# SN32F290 register map
Vendor: SONIX; File version: 2026.10.03
CPU: CM0 r0p0, little endian, no MPU, no FPU, 2 interrupt priority bits
Registers are 32-bit, read-write, reset 0x0 unless marked. A register's access mark holds for its fields unless they carry their own. Offsets are from the block's base; [hi:lo] are bit positions.

## SN_SYS0 — System Control Registers 0
Base 0x40060000
0x00 ANBCTRL reset 0x1 (reset mask 0x35) — Offset:0x00 Analog Block Control Register
  [10:5] EHSFREQ — EHS XTAL frequency range
    0=Low_4 (Less equal than 12MHz); 1=High_23 (Greater than 12MHz)
  [8:4] EHSEN — EHS XTAL enable
    0=Disable_434 (Disable EHS Xtal); 1=Enable_145 (Enable EHS Xtal)
  [4:2] ELSEN — ELS XTAL enable
    0=Disable_434 (Disable ELS Xtal); 1=Enable_145 (Enable ELS Xtal)
  [0] IHRCEN — IHRC enable
    0=Disable_434 (Disable IHRC); 1=Enable_145 (Enable IHRC)
0x04 PLLCTRL (reset mask 0x9027) — Offset:0x04 PLL Control Register
  [30:15] PLLEN — PLL enable
    0=Disable_434 (Disable PLL); 1=Enable_145 (Enable PLL)
  [24:12] PLLCLKSEL — PLL clock source
    0=IHRC_3 (12MHz); 1=EHS_XTAL_5 (10MHz~25MHz)
  [10:5] PSEL — P value
    0=V_2 (P=2); 1=V_4_16 (P=4)
  [2:0] MSEL — M value
    0=V_000b_5 (M=4); 1=V_001b_13 (M=6); 2=V_010b_18 (M=8); 3=V_011b_3 (M=10); 4=V_100b (M=12)
0x08 CSST ro reset 0x1 (reset mask 0x55) — Offset:0x08 Clock Source Status Register
  [12:6] PLLRDY — PLL ready flag
    0=Not_Locked (PLL is Not locked); 1=Locked (PLL is locked)
  [8:4] EHSRDY — EHS XTAL ready flag
    0=Not_Ready_4 (EHS Xtal is Not Ready); 1=Ready_8 (EHS Xtal is Ready)
  [4:2] ELSRDY — ELS XTAL ready flag
    0=Not_Ready_4 (ELS Xtal is Not Ready); 1=Ready_8 (ELS Xtal is Ready)
  [0] IHRCRDY — IHRC ready flag
    0=Not_Ready_4 (IHRC is Not Ready); 1=Ready_8 (IHRC is Ready)
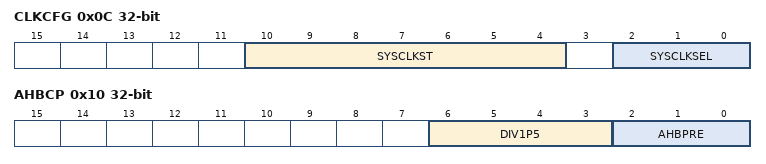
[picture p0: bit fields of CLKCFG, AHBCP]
0x0C CLKCFG (reset mask 0x77) — Offset:0x0C System Clock Configuration Register
  [10:4] SYSCLKST ro — System clock switch status
    0=IHRC_3 (IHRC is used as system clock); 1=ILRC_2 (ILRC is used as system clock); 2=EHS_XTAL_5 (EHS XTAL is used as system clock); 3=ELS_XTAL_2 (ELS XTAL is used as system clock); 4=PLL (PLL output is used as system clock)
  [2:0] SYSCLKSEL — System clock source selection
    0=IHRC_3 (HCLK=IHRC); 1=ILRC_2 (HCLK=ILRC); 2=EHS_XTAL_5 (HCLK=EHS XTAL); 3=ELS_XTAL_2 (HCLK=ELS XTAL); 4=PLL_Output (HCLK=PLL output)
0x10 AHBCP (reset mask 0xF) — Offset:0x10 AHB Clock Prescale Register
  [6:3] DIV1P5 — SYSCLK prescaler
    0=DIV1 (SYSCLK = SYSCLK/1); 1=SYSCLK = SYSCLK/1.5
  [2:0] AHBPRE — AHB clock source prescaler
    0=V_000b_5 (FAHB=FSYSCLK/1); 1=V_001b_13 (FAHB=FSYSCLK/2); 2=V_010b_18 (FAHB=FSYSCLK/4); 3=V_011b_3 (FAHB=FSYSCLK/8); 4=V_100b (FAHB=FSYSCLK/16); 5=V_101b_5 (FAHB=FSYSCLK/32); 6=V_110b (FAHB=FSYSCLK/64); 7=V_111b_11 (FAHB=FSYSCLK/128)
0x14 RSTST reset 0x11 (reset mask 0x1F) — Offset:0x14 System Reset Status Register
  [8:4] PORRSTF — POR reset flag
    0=V_0_164 (No POR occurred); 1=V_1_374 (POR occurred)
  [6:3] EXTRSTF — External reset flag
    0=V_0_164 (No Extenral reset occurred); 1=V_1_374 (External reset occurred)
  [4:2] LVDRSTF — LVD reset flag
    0=V_0_164 (No LVD reset occurred); 1=V_1_374 (LVD reset occurred)
  [2:1] WDTRSTF — WDT reset flag
    0=V_0_164 (No WDT reset occurred); 1=V_1_374 (WDT reset occurred)
  [0] SWRSTF — Software reset flag
    0=V_0_164 (No SW reset occurred); 1=V_1_374 (SW reset occurred)
0x18 LVDCTRL reset 0x33 (reset mask 0xC077) — Offset:0x18 LVD Control Register
  [30:15] LVDEN — LVD enable
    0=Diable_2 (Disable LVD); 1=Enable_145 (Enable LVD)
  [28:14] LVDRSTEN — LVD Reset enable
    0=Diable_2 (Disable LVD reset); 1=Enable_145 (Enable LVD reset)
  [10:4] LVDINTLVL — LVD interrupt level
    3=V_2_70V_2 (LVD interrupt threshold is 2.70V); 4=V_3_00V (LVD interrupt threshold is 3.00V); 5=V_3_60V_2 (LVD interrupt threshold is 3.60V)
  [2:0] LVDRSTLVL — LVD reset level
    3=V_2_70V_2 (LVD reset threshold is 2.70V); 4=V_3_00V (LVD reset threshold is 3.00V); 5=V_3_60V_2 (LVD reset threshold is 3.60V)
0x1C EXRSTCTRL reset 0x1 — Offset:0x1C External Reset Pin Control Register
  [0] RESETDIS — External reset pin disable
    0=Enable_145 (P3.7 acts as nRESET pin); 1=Disable_434 (P3.7 acts as GPIO pin)
0x20 SWDCTRL — Offset:0x20 SWD Pin Control Register
  [0] SWDDIS — SWD pin disable
    0=Enable_145 (Enable SWD pins); 1=Disable_434 (Disable SWD pins)
0x24 IVTM (reset mask 0xFFFF0007) — Offset:0x24 Interrupt Vector Table Mapping register
  [47:16] IVTMKEY wo — IVTM register key
  [2:0] IVTM — Interrupt table mapping selection
    0=V_000b_5 (Map to Boot ROM); 1=V_001b_13 (Map to User ROM 1); 2=V_010b_18 (Map to SRAM); 3=V_011b_3 (Map to User ROM 2); 4=V_100b (Map to User ROM 3); 5=V_101b_5 (Map to User ROM 4)
0x28 NDTCTRL (reset mask 0x2) — Offset:0x28 Noise Detect Control Register
  [2:1] NDT5V_IE — NDT for VDD 5V interrupt enable bit
    0=Disable_434 (Disable NDT5V interrupt); 1=Enable_145 (Enable NDT5V interrupt)
0x2C NDTSTS (reset mask 0x2) — Offset:0x2C Noise Detect Status Register
  [2:1] NDT5V_DET — Power noise status of NDT5V
    0=No_58 (No power noise is detected); 1=Detected (Power noise is detected by NDT5V IP)
0x34 IHRCADJ (reset mask 0xFFFF0FF3) — Offset:0x34 IHRC Frequency Adjustment register
  [47:16] SYSKEY wo — System register key
  [15:4] ADJ — IHRC frequency adjusting bits
  [2:1] DIR — IHRC frequency adjusting direction bit
    0=Positive direction; 1=Negative direction
  [0] ADJEN — IHRC frequency adjustment enable bit
    0=Disable_434 (Disable IHRC frequency adjustment); 1=Enable_145 (Enable IHRC frequency adjustment)
